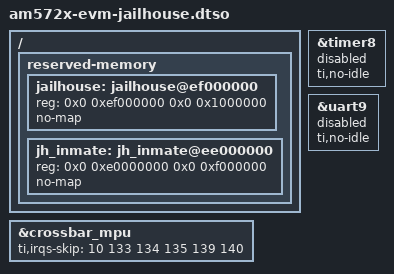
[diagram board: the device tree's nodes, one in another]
/dts-v1/;
/plugin/;

/ {
  fragment@101 {
	target-path = "/";

	__overlay__ {
		reserved-memory {
			jailhouse: jailhouse@ef000000 {
				reg = <0x0 0xef000000 0x0 0x1000000>;
				no-map;
				status = "okay";
			};

			jh_inmate: jh_inmate@ee000000 {
				reg = <0x0 0xe0000000 0x0 0xf000000>;
				no-map;
				status = "okay";
			};
		};
	};
  };
};

&crossbar_mpu {
	ti,irqs-skip = <10 133 134 135 139 140>;
};

&timer8 {
	status = "disabled";
	ti,no-idle;
};

&uart9 {
	status = "disabled";
	ti,no-idle;
};
